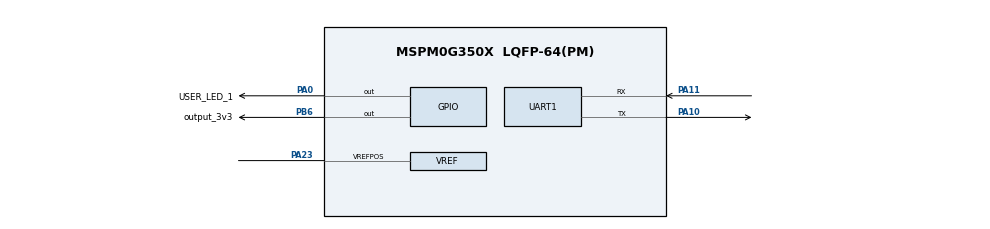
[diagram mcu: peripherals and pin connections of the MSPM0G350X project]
/**
 * @cliArgs --device "MSPM0G350X" --part "Default" --package "LQFP-64(PM)" --product "mspm0_sdk@2.10.00.04"
 * @versions {"tool":"1.26.2+4477"}
 */

/**
 * Import the modules used in this configuration.
 */
const ADC12  = scripting.addModule("/ti/driverlib/ADC12", {}, false);
const ADC121 = ADC12.addInstance();
const Board  = scripting.addModule("/ti/driverlib/Board");
const GPIO   = scripting.addModule("/ti/driverlib/GPIO", {}, false);
const GPIO1  = GPIO.addInstance();
const GPIO2  = GPIO.addInstance();
const SYSCTL = scripting.addModule("/ti/driverlib/SYSCTL");
const UART   = scripting.addModule("/ti/driverlib/UART", {}, false);
const UART1  = UART.addInstance();
const VREF   = scripting.addModule("/ti/driverlib/VREF");

/**
 * Write custom configuration values to the imported modules.
 */
ADC121.$name                      = "ADC12_0";
ADC121.sampClkSrc                 = "DL_ADC12_CLOCK_ULPCLK";
ADC121.sampClkDiv                 = "DL_ADC12_CLOCK_DIVIDE_8";
ADC121.adcMem0chansel             = "DL_ADC12_INPUT_CHAN_2";
ADC121.sampleTime0                = "125 us";
ADC121.enabledInterrupts          = ["DL_ADC12_INTERRUPT_MEM0_RESULT_LOADED"];
ADC121.adcMem0vref                = "VREF";
ADC121.powerDownMode              = "DL_ADC12_POWER_DOWN_MODE_MANUAL";
ADC121.peripheral.$assign         = "ADC0";
ADC121.peripheral.adcPin2.$assign = "PA25";
ADC121.adcPin2Config.$name        = "ti_driverlib_gpio_GPIOPinGeneric0";
ADC121.adcPin2Config.enableConfig = true;


GPIO1.$name                          = "GPIO_LEDS";
GPIO1.port                           = "PORTA";
GPIO1.portSegment                    = "Lower";
GPIO1.associatedPins[0].$name        = "USER_LED_1";
GPIO1.associatedPins[0].assignedPin  = "0";
GPIO1.associatedPins[0].initialValue = "SET";
GPIO1.associatedPins[0].pin.$assign  = "PA0";

GPIO2.$name                          = "output3v";
GPIO2.portSegment                    = "Lower";
GPIO2.port                           = "PORTB";
GPIO2.associatedPins[0].$name        = "output_3v3";
GPIO2.associatedPins[0].assignedPin  = "6";
GPIO2.associatedPins[0].initialValue = "SET";
GPIO2.associatedPins[0].pin.$assign  = "PB6";

SYSCTL.forceDefaultClkConfig = true;
SYSCTL.clockTreeEn           = true;

UART1.$name                    = "UART_0";
UART1.rxFifoThreshold          = "DL_UART_RX_FIFO_LEVEL_ONE_ENTRY";
UART1.enableDMARX              = false;
UART1.enableDMATX              = false;
UART1.ovsRate                  = "16";
UART1.uartClkSrc               = "BUSCLK";
UART1.enabledInterrupts        = ["RX","TX"];
UART1.enableFIFO               = false;
UART1.peripheral.rxPin.$assign = "PA11";
UART1.peripheral.txPin.$assign = "PA10";
UART1.txPinConfig.$name        = "ti_driverlib_gpio_GPIOPinGeneric2";
UART1.txPinConfig.enableConfig = true;
UART1.rxPinConfig.$name        = "ti_driverlib_gpio_GPIOPinGeneric3";

VREF.basicIntVolt                  = "DL_VREF_BUFCONFIG_OUTPUT_2_5V";
VREF.advClockConfigEnable          = true;
VREF.advClkSrc                     = "DL_VREF_CLOCK_BUSCLK";
VREF.peripheral.$assign            = "VREF";
VREF.peripheral.vrefPosPin.$assign = "PA23";
VREF.vrefPosPinConfig.$name        = "ti_driverlib_gpio_GPIOPinGeneric1";

/**
 * Pinmux solution for unlocked pins/peripherals. This ensures that minor changes to the automatic solver in a future
 * version of the tool will not impact the pinmux you originally saw.  These lines can be completely deleted in order to
 * re-solve from scratch.
 */
Board.peripheral.$suggestSolution          = "DEBUGSS";
Board.peripheral.swclkPin.$suggestSolution = "PA20";
Board.peripheral.swdioPin.$suggestSolution = "PA19";
UART1.peripheral.$suggestSolution          = "UART0";
